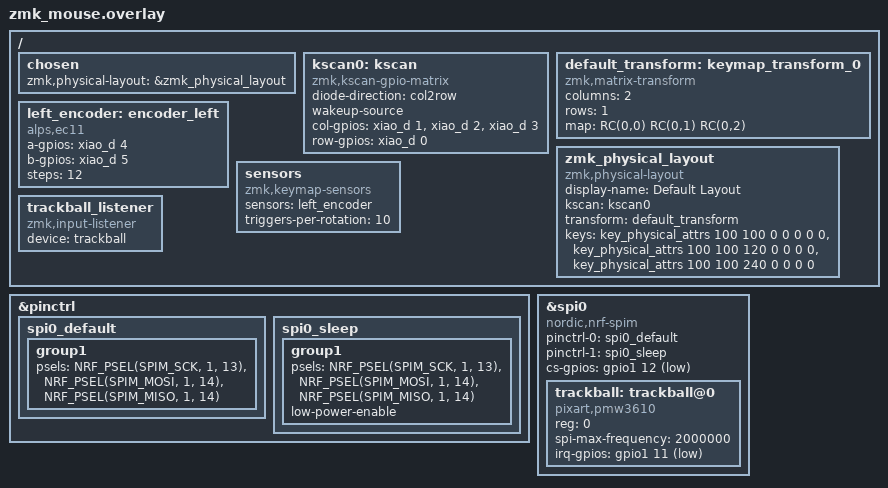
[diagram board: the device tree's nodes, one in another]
#include <dt-bindings/zmk/matrix_transform.h>
#include <physical_layouts.dtsi>

#define ZMK_POINTING_DEFAULT_SCRL_VAL 100

/ {
    chosen {
        zmk,physical-layout = &zmk_physical_layout;
    };
    
    kscan0: kscan {
        compatible = "zmk,kscan-gpio-matrix";
        diode-direction = "col2row";
        wakeup-source;

        col-gpios
            = <&xiao_d  1 GPIO_ACTIVE_HIGH>
            , <&xiao_d  2 GPIO_ACTIVE_HIGH> 
            , <&xiao_d  3 GPIO_ACTIVE_HIGH> 
            ;
        row-gpios
            = <&xiao_d 0 (GPIO_ACTIVE_HIGH | GPIO_PULL_DOWN)> 
            ;
    };

    default_transform: keymap_transform_0 {
        compatible = "zmk,matrix-transform";
        columns = <2>;
        rows = <1>;               
        map = <
            RC(0,0) RC(0,1) RC(0,2)
        >;
    };

    zmk_physical_layout: zmk_physical_layout {
        compatible = "zmk,physical-layout";
        display-name = "Default Layout";
        kscan = <&kscan0>;
        transform = <&default_transform>;

        keys  //                 w   h    x    y     rot    rx    ry
        = <&key_physical_attrs 100 100    0    0       0     0     0>
        , <&key_physical_attrs 100 100  120    0       0     0     0>
        , <&key_physical_attrs 100 100  240    0       0     0     0>
        ;
    };

    left_encoder: encoder_left {
        compatible = "alps,ec11";
        a-gpios = <&xiao_d 4 (GPIO_ACTIVE_HIGH | GPIO_PULL_UP)>;
        b-gpios = <&xiao_d 5 (GPIO_ACTIVE_HIGH | GPIO_PULL_UP)>;
        steps = <12>;
        status = "okay";
    };

    sensors: sensors {
        compatible = "zmk,keymap-sensors";
        sensors = <&left_encoder>;
        triggers-per-rotation = <10>;
    };

    trackball_listener {
        compatible = "zmk,input-listener";
        device = <&trackball>;

    };
};

&pinctrl {
    spi0_default: spi0_default {
        group1 {
            psels = <NRF_PSEL(SPIM_SCK, 1, 13)>,
                <NRF_PSEL(SPIM_MOSI, 1, 14)>,
                <NRF_PSEL(SPIM_MISO, 1, 14)>;
        };
    };

    spi0_sleep: spi0_sleep {
        group1 {
            psels = <NRF_PSEL(SPIM_SCK, 1, 13)>,
                <NRF_PSEL(SPIM_MOSI, 1, 14)>,
                <NRF_PSEL(SPIM_MISO, 1, 14)>;
            low-power-enable;
        };
    };
};

&spi0 {
    status = "okay";
    compatible = "nordic,nrf-spim";
    pinctrl-0 = <&spi0_default>;
    pinctrl-1 = <&spi0_sleep>;
    pinctrl-names = "default", "sleep";
    cs-gpios = <&gpio1 12 GPIO_ACTIVE_LOW>;


    trackball: trackball@0 {
        status = "okay";
        compatible = "pixart,pmw3610";
        reg = <0>;
        spi-max-frequency = <2000000>;
        irq-gpios = <&gpio1 11 (GPIO_ACTIVE_LOW | GPIO_PULL_UP)>;
        
        /*   optional features   */
        // snipe-layers = <1>;
        // scroll-layers = <2 3>;
        // automouse-layer = <4>;
    };
};
